# N571P032_v3 register map
File version: 1.0
Registers are 32-bit, read-write, reset 0x0 unless marked. A register's access mark holds for its fields unless they carry their own. Offsets are from the block's base; [hi:lo] are bit positions; 'fields as' and 'values as' point back to an identical list.

## CLK — CLK Register Map
Base 0x50000200
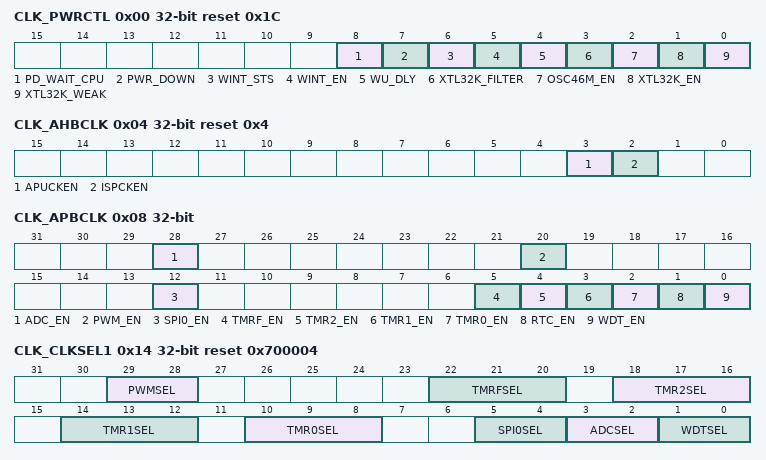
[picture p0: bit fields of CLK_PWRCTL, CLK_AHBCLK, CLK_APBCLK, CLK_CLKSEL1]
0x00 CLK_PWRCTL reset 0x1C — System Power Control Register
  [8] PD_WAIT_CPU — This Bit Controls the Power Down Entry Condition. Please refer to PWR_DOWN bit for the usage of PD_WAIT_CPU bit. The following is a brief description of PD_WAIT_CPU bit.
    0=Chip is at normal mode. Note that PWR_DOWN cannot be set to 1 when PD_WAIT_CPU value remains at 0, otherwise the chip may not wake up normally; 1=Chip waits to enter power-down mode
  [7] PWR_DOWN — System Power Down Active Or Enable Bit
    0=Chip operates at normal mode; 1=Chip is standing by power-down entry condition
  [6] WINT_STS — Chip Power Down Wake Up Status Flag. Set by "power down wake up", it indicates that resume from power down mode. The flag is set if the GPIO, WDT or RTC wakeup. Note: Write 1 to clear the bit.
  [5] WINT_EN — Enable Interrupt When Wake Up From Power Down Mode
    0=Disable; 1=Enable. The interrupt will occur when MCU wakes up from power down mode
  [4] WU_DLY — Enable the Wake Up Delay Time Selection. When the chip wakes up from power down, the clock control will delay some times as selection to wait LDO33 stable. 1: Delay 200us for LDO33 stable. 0: Delay 60us for LDO33 stable.
  [3] XTL32K_FILTER — Filter the XTL32K output clock. Note: High level of XTL32K must keep 112 HCLK for recognition valid, when this bit is enabled.
    0=Disable, XTL32K output clock without filter; 1=Enable, XTL32K output clock will be filtered to avoid glitch occurs
  [2] OSC46M_EN — Internal 46MHz RC Oscillator Control. After reset, this bit is "1".
    0=46MHz oscillation is disabled; 1=46MHz oscillation is enabled
  [1] XTL32K_EN — External 32.768KHz Crystal Control. After reset, this bit is "0".
    0=32.768KHz Crystal is disabled; 1=32.768KHz Crystal is enabled
  [0] XTL32K_WEAK — XTL32K weak mode
    0=Normal mode; 1=Weak mode
0x04 CLK_AHBCLK reset 0x4 — AHB Device Clock Enable Control Register
  [3] APUCKEN — APU Clock Enable Control
    0=To disable the APU engine clock; 1=To enable the APU engine clock
  [2] ISPCKEN — OTP ISP Controller Clock Enable Control. The OTP ISP engine clock always is from 46MHz RC oscillator.
    0=Disable the OTP ISP engine clock; 1=Enable the OTP ISP engine clock
0x08 CLK_APBCLK — APB Device Clock Enable Control Register
  [all] fields
    0=Disable; 1=Enable
  [28] ADC_EN — Audio Analog-Digital-Converter (ADC) Clock Enable Control
  [20] PWM_EN — PWM Block Clock Enable Control
  [12] SPI0_EN — SPI0 Clock Enable Control
  [5] TMRF_EN — TimerF Clock Enable Control
  [4] TMR2_EN — Timer2 Clock Enable Control
  [3] TMR1_EN — Timer1 Clock Enable Control
  [2] TMR0_EN — Timer0 Clock Enable Control
  [1] RTC_EN — Real-Time-Clock APB Interface Clock Control. This bit is used to control the RTC APB clock only. The RTC engine clock source is from the 32.768KHz crystal.
  [0] WDT_EN — Watchdog Clock Enable Control. This bit is the protected bit. To program this bit needs an open lock sequence, write "59h", "16h", "88h" to register SYS_REGLCTL to un-lock this bit. Refer to the register SYS_REGLCTL at address SYS_BA+0x100. The default bit value is set according to the Flash Controller User Configuration Register CONFIG[31].
0x10 CLK_CLKSEL0 reset 0x7 — Clock Source Select Control Register 0
  [2:0] HCLKSEL — HCLK Clock Source Select . Note: 1. When power on, 23MHz RC is selected as HCLK clock source. 2. Before clock switch, the related clock sources (pre-select and new-select) must be turned on.
    0=clock source from XTL_32K; 2=clock source from PLL_23M; 4=clock source from PLL_23M; 7=clock source from RC_23M
0x14 CLK_CLKSEL1 reset 0x700004 — Clock Source Select Control Register 1
  [29:28] PWMSEL — PWM Timer Clock Source Select
    0=Clock source from HCLK; 1=Clock source from XTL_32K; 2=Equivalent with "00"; 3=Clock source from RC_46M
  [22:20] TMRFSEL — TimerF Clock Source Select
    0=Clock source from external XTL_32K/32,; 1=Clock source from external XTL_32K/(4x32),; 6=Clock source from RC_46M/32768,; 7=Clock source from RC_46M/(4x32768),
  [18:16] TMR2SEL — Timer2 Clock Source Select
    0=Clock source from HCLK; 1=Clock source from XTL_32K. Clock source from RC_46M; 2=Equivalent with "000"; 3=Equivalent with "000"
  [14:12] TMR1SEL — Timer1 Clock Source Select
    0=Clock source from HCLK; 1=Clock source from XTL_32K. Clock source from RC_46M; 2=Equivalent with "000"; 3=Clock source from external trigger
  [10:8] TMR0SEL — Timer0 Clock Source Select
    values as TMR1SEL
  [5:4] SPI0SEL — SPI0 Clock Source Select
    0=Clock source from HCLK; 1=Clock source from PLL_FOUT. Clock source from RC_46M
  [3:2] ADCSEL — ADC Clock Source Select
    0=Clock source from PLL_FOUT,; 1=Clock source from HCLK,. Clock source from RC_46M
  [1:0] WDTSEL — Watchdog Timer Clock Source Selection (Write Protect). These bits are protected bits. To program these bits needs an open lock sequence, write "59h", "16h", "88h" to SYS_REGLCTL to un-lock these bits. Refer to the register SYS_REGLCTL at address SYS_BA+0x100..
    0=Clock source from HCLK/2048,; 1=Clock source from XTL_32K,; 2=Clock source from PLL_FOUT,; 3=Clock source from RC_23M
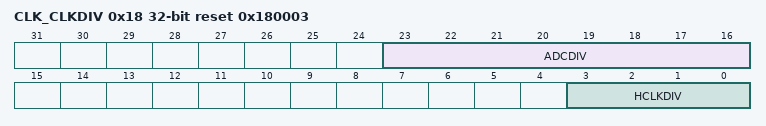
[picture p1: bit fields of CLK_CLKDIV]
0x18 CLK_CLKDIV reset 0x180003 — Clock Divider Number Register
  [23:16] ADCDIV — ADC Clock Divide Number From ADC Clock Source. The ADC engine clock must meet the constraint: ADCLK ( HCKL/2.
  [3:0] HCLKDIV — HCLK Clock Divide Number From HCLK Clock Source
0x20 CLK_PLLCON reset 0x3 — PLL Control Register
